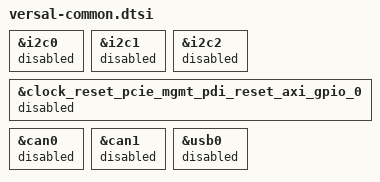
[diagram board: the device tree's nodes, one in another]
/include/ "fragments/mango-drivers-smi.dtsi"

// Disable lpd peripherals controlled by r5
&i2c0 {
	status = "disabled";
};
&i2c1 {
	status = "disabled";
};
&i2c2 {
	status = "disabled";
};

// workaround for GPIO H/W bug
&clock_reset_pcie_mgmt_pdi_reset_axi_gpio_0 {
	status = "disabled";
};

// not used
&can0 {
	status = "disabled";
};
&can1 {
	status = "disabled";
};
&usb0 {
	status = "disabled";
};
